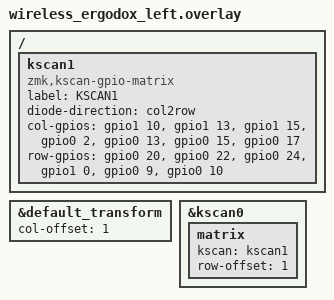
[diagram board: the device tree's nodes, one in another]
/*
 * Copyright (c) 2021 The ZMK Contributors
 *
 * SPDX-License-Identifier: MIT
 */

#include "wireless_ergodox.dtsi"

&default_transform {
    col-offset = <1>;
};

&kscan0 {
    // add key matrix to kscan0
    matrix {
        kscan = <&kscan1>;
        row-offset = <1>; // ...and shift it to not overlap
    };
};

/ {
    kscan1: kscan1 {
        compatible = "zmk,kscan-gpio-matrix";
        label = "KSCAN1";
        diode-direction = "col2row";

        col-gpios
            = <&gpio1 10 GPIO_ACTIVE_HIGH>
            , <&gpio1 13 GPIO_ACTIVE_HIGH>
            , <&gpio1 15 GPIO_ACTIVE_HIGH>
            , <&gpio0  2 GPIO_ACTIVE_HIGH>
            , <&gpio0 13 GPIO_ACTIVE_HIGH>
            , <&gpio0 15 GPIO_ACTIVE_HIGH>
            , <&gpio0 17 GPIO_ACTIVE_HIGH>
            ;

        row-gpios
            = <&gpio0 20 (GPIO_ACTIVE_HIGH | GPIO_PULL_DOWN)>
            , <&gpio0 22 (GPIO_ACTIVE_HIGH | GPIO_PULL_DOWN)>
            , <&gpio0 24 (GPIO_ACTIVE_HIGH | GPIO_PULL_DOWN)>
            , <&gpio1  0 (GPIO_ACTIVE_HIGH | GPIO_PULL_DOWN)>
            , <&gpio0  9 (GPIO_ACTIVE_HIGH | GPIO_PULL_DOWN)>
            , <&gpio0 10 (GPIO_ACTIVE_HIGH | GPIO_PULL_DOWN)>
            ;
    };
};
